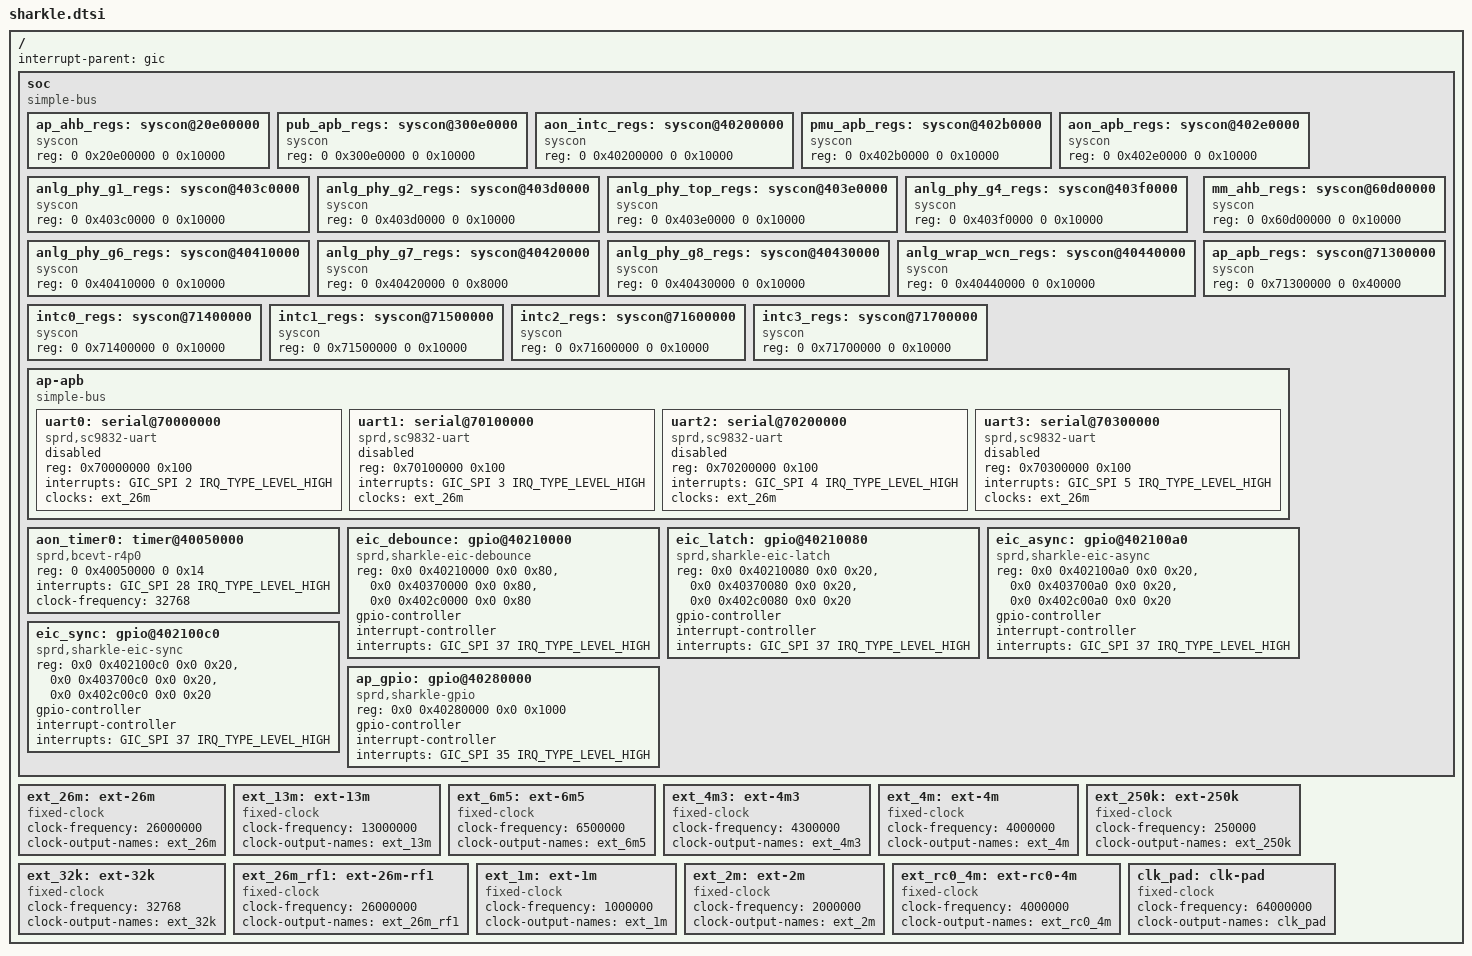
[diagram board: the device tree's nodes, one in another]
/*
 * Spreadtrum sharkle platform DTS file
 *
 * Copyright (C) 2018, Spreadtrum Communications Inc.
 *
 * SPDX-License-Identifier: (GPL-2.0+ OR MIT)
 */

/ {
	interrupt-parent = <&gic>;
	#address-cells = <2>;
	#size-cells = <2>;

	soc: soc {
		compatible = "simple-bus";
		#address-cells = <2>;
		#size-cells = <2>;
		ranges;

		ap_ahb_regs: syscon@20e00000 {
			compatible = "syscon";
			reg = <0 0x20e00000 0 0x10000>;
		};

		pub_apb_regs: syscon@300e0000 {
			compatible = "syscon";
			reg = <0 0x300e0000 0 0x10000>;
		};

		aon_intc_regs: syscon@40200000 {
			compatible = "syscon";
			reg = <0 0x40200000 0 0x10000>;
		};

		pmu_apb_regs: syscon@402b0000 {
			compatible = "syscon";
			reg = <0 0x402b0000 0 0x10000>;
		};

		aon_apb_regs: syscon@402e0000 {
			compatible = "syscon";
			reg = <0 0x402e0000 0 0x10000>;
		};

		anlg_phy_g1_regs: syscon@403c0000 {
			compatible = "syscon";
			reg = <0 0x403c0000 0 0x10000>;
		};

		anlg_phy_g2_regs: syscon@403d0000 {
			compatible = "syscon";
			reg = <0 0x403d0000 0 0x10000>;
		};

		anlg_phy_top_regs: syscon@403e0000 {
			compatible = "syscon";
			reg = <0 0x403e0000 0 0x10000>;
		};

		anlg_phy_g4_regs: syscon@403f0000 {
			compatible = "syscon";
			reg = <0 0x403f0000 0 0x10000>;
		};

		anlg_phy_g6_regs: syscon@40410000 {
			compatible = "syscon";
			reg = <0 0x40410000 0 0x10000>;
		};

		anlg_phy_g7_regs: syscon@40420000 {
			compatible = "syscon";
			reg = <0 0x40420000 0 0x8000>;
		};

		anlg_phy_g8_regs: syscon@40430000 {
			compatible = "syscon";
			reg = <0 0x40430000 0 0x10000>;
		};

		anlg_wrap_wcn_regs: syscon@40440000 {
			compatible = "syscon";
			reg = <0 0x40440000 0 0x10000>;
		};

		mm_ahb_regs: syscon@60d00000 {
			compatible = "syscon";
			reg = <0 0x60d00000 0 0x10000>;
		};

		ap_apb_regs: syscon@71300000 {
			compatible = "syscon";
			reg = <0 0x71300000 0 0x40000>;
		};

		intc0_regs: syscon@71400000 {
			compatible = "syscon";
			reg = <0 0x71400000 0 0x10000>;
		};


		intc1_regs: syscon@71500000 {
			compatible = "syscon";
			reg = <0 0x71500000 0 0x10000>;
		};

		intc2_regs: syscon@71600000 {
			compatible = "syscon";
			reg = <0 0x71600000 0 0x10000>;
		};

		intc3_regs: syscon@71700000 {
			compatible = "syscon";
			reg = <0 0x71700000 0 0x10000>;
		};

		ap-apb {
			compatible = "simple-bus";
			#address-cells = <1>;
			#size-cells = <1>;
			ranges;

			uart0: serial@70000000 {
				compatible = "sprd,sc9832-uart",
					     "sprd,sc9836-uart";
				reg = <0x70000000 0x100>;
				interrupts = <GIC_SPI 2 IRQ_TYPE_LEVEL_HIGH>;
				clocks = <&ext_26m>;
				status = "disabled";
			};

			uart1: serial@70100000 {
				compatible = "sprd,sc9832-uart",
					     "sprd,sc9836-uart";
				reg = <0x70100000 0x100>;
				interrupts = <GIC_SPI 3 IRQ_TYPE_LEVEL_HIGH>;
				clocks = <&ext_26m>;
				status = "disabled";
			};

			uart2: serial@70200000 {
				compatible = "sprd,sc9832-uart",
					     "sprd,sc9836-uart";
				reg = <0x70200000 0x100>;
				interrupts = <GIC_SPI 4 IRQ_TYPE_LEVEL_HIGH>;
				clocks = <&ext_26m>;
				status = "disabled";
			};

			uart3: serial@70300000 {
				compatible = "sprd,sc9832-uart",
					     "sprd,sc9836-uart";
				reg = <0x70300000 0x100>;
				interrupts = <GIC_SPI 5 IRQ_TYPE_LEVEL_HIGH>;
				clocks = <&ext_26m>;
				status = "disabled";
			};
		};

		aon_timer0: timer@40050000 {
			compatible = "sprd,bcevt-r4p0";
			reg = <0 0x40050000 0 0x14>;
			interrupts = <GIC_SPI 28 IRQ_TYPE_LEVEL_HIGH>;
			clock-frequency = <32768>;
		};

		eic_debounce: gpio@40210000 {
			compatible = "sprd,sharkle-eic-debounce";
			reg = <0x0 0x40210000 0x0 0x80>,
			      <0x0 0x40370000 0x0 0x80>,
			      <0x0 0x402c0000 0x0 0x80>;
			gpio-controller;
			#gpio-cells = <2>;
			interrupt-controller;
			#interrupt-cells = <2>;
			interrupts = <GIC_SPI 37 IRQ_TYPE_LEVEL_HIGH>;
		};

		eic_latch: gpio@40210080 {
			compatible = "sprd,sharkle-eic-latch";
			reg = <0x0 0x40210080 0x0 0x20>,
			      <0x0 0x40370080 0x0 0x20>,
			      <0x0 0x402c0080 0x0 0x20>;
			gpio-controller;
			#gpio-cells = <2>;
			interrupt-controller;
			#interrupt-cells = <2>;
			interrupts = <GIC_SPI 37 IRQ_TYPE_LEVEL_HIGH>;
		};

		eic_async: gpio@402100a0 {
			compatible = "sprd,sharkle-eic-async";
			reg = <0x0 0x402100a0 0x0 0x20>,
			      <0x0 0x403700a0 0x0 0x20>,
			      <0x0 0x402c00a0 0x0 0x20>;
			gpio-controller;
			#gpio-cells = <2>;
			interrupt-controller;
			#interrupt-cells = <2>;
			interrupts = <GIC_SPI 37 IRQ_TYPE_LEVEL_HIGH>;
		};

		eic_sync: gpio@402100c0 {
			compatible = "sprd,sharkle-eic-sync";
			reg = <0x0 0x402100c0 0x0 0x20>,
			      <0x0 0x403700c0 0x0 0x20>,
			      <0x0 0x402c00c0 0x0 0x20>;
			gpio-controller;
			#gpio-cells = <2>;
			interrupt-controller;
			#interrupt-cells = <2>;
			interrupts = <GIC_SPI 37 IRQ_TYPE_LEVEL_HIGH>;
		};

		ap_gpio: gpio@40280000 {
			compatible = "sprd,sharkle-gpio";
			reg = <0x0 0x40280000 0x0 0x1000>;
			gpio-controller;
			#gpio-cells = <2>;
			interrupt-controller;
			#interrupt-cells = <2>;
			interrupts = <GIC_SPI 35 IRQ_TYPE_LEVEL_HIGH>;
		};
	};

	ext_26m: ext-26m {
		compatible = "fixed-clock";
		#clock-cells = <0>;
		clock-frequency = <26000000>;
		clock-output-names = "ext_26m";
	};

	ext_13m: ext-13m {
		compatible = "fixed-clock";
		#clock-cells = <0>;
		clock-frequency = <13000000>;
		clock-output-names = "ext_13m";
	};

	ext_6m5: ext-6m5 {
		compatible = "fixed-clock";
		#clock-cells = <0>;
		clock-frequency = <6500000>;
		clock-output-names = "ext_6m5";
	};

	ext_4m3: ext-4m3 {
		compatible = "fixed-clock";
		#clock-cells = <0>;
		clock-frequency = <4300000>;
		clock-output-names = "ext_4m3";
	};

	ext_4m: ext-4m {
		compatible = "fixed-clock";
		#clock-cells = <0>;
		clock-frequency = <4000000>;
		clock-output-names = "ext_4m";
	};

	ext_250k: ext-250k {
		compatible = "fixed-clock";
		#clock-cells = <0>;
		clock-frequency = <250000>;
		clock-output-names = "ext_250k";
	};

	ext_32k: ext-32k {
		compatible = "fixed-clock";
		#clock-cells = <0>;
		clock-frequency = <32768>;
		clock-output-names = "ext_32k";
	};

	ext_26m_rf1: ext-26m-rf1 {
		compatible = "fixed-clock";
		#clock-cells = <0>;
		clock-frequency = <26000000>;
		clock-output-names = "ext_26m_rf1";
	};

	ext_1m: ext-1m {
		compatible = "fixed-clock";
		#clock-cells = <0>;
		clock-frequency = <1000000>;
		clock-output-names = "ext_1m";
	};

	ext_2m: ext-2m {
		compatible = "fixed-clock";
		#clock-cells = <0>;
		clock-frequency = <2000000>;
		clock-output-names = "ext_2m";
	};

	ext_rc0_4m: ext-rc0-4m {
		compatible = "fixed-clock";
		#clock-cells = <0>;
		clock-frequency = <4000000>;
		clock-output-names = "ext_rc0_4m";
	};

	clk_pad: clk-pad {
		compatible = "fixed-clock";
		#clock-cells = <0>;
		clock-frequency = <64000000>;
		clock-output-names = "clk_pad";
	};
};
